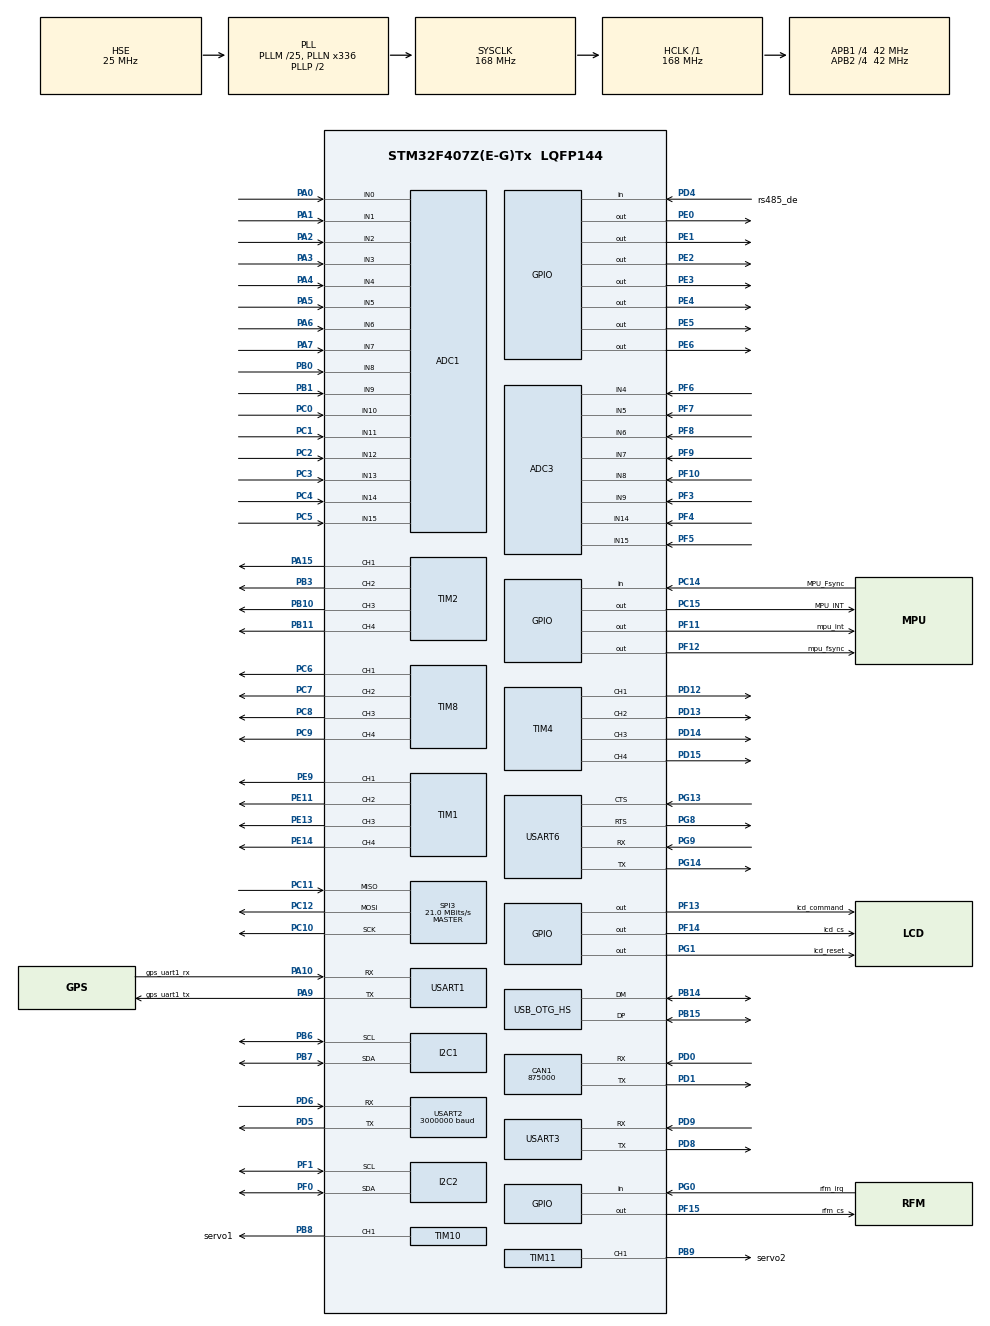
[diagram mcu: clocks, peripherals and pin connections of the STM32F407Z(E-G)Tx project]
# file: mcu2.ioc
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ADC1.ClockPrescaler=ADC_CLOCK_SYNC_PCLK_DIV4
ADC1.Rank-1\#ChannelRegularConversion=1
ADC1.master=1
ADC2.Channel-3\#ChannelRegularConversion=ADC_CHANNEL_0
ADC2.ClockPrescaler=ADC_CLOCK_SYNC_PCLK_DIV4
ADC2.NbrOfConversionFlag=1
ADC2.Rank-3\#ChannelRegularConversion=1
ADC2.SamplingTime-3\#ChannelRegularConversion=ADC_SAMPLETIME_3CYCLES
ADC3.Channel-0\#ChannelRegularConversion=ADC_CHANNEL_0
ADC3.ClockPrescaler=ADC_CLOCK_SYNC_PCLK_DIV4
ADC3.NbrOfConversionFlag=1
ADC3.Rank-0\#ChannelRegularConversion=1
ADC3.SamplingTime-0\#ChannelRegularConversion=ADC_SAMPLETIME_3CYCLES
CAN1.BS1=CAN_BS1_1TQ
CAN1.BS2=CAN_BS2_1TQ
CAN1.CalculateBaudRate=875000
CAN1.CalculateTimeBit=1142
CAN1.CalculateTimeQuantum=380.95238095238096
Dma.ADC1.2.Direction=DMA_PERIPH_TO_MEMORY
Dma.ADC1.2.FIFOMode=DMA_FIFOMODE_ENABLE
Dma.ADC1.2.FIFOThreshold=DMA_FIFO_THRESHOLD_FULL
Dma.ADC1.2.Instance=DMA2_Stream0
Dma.ADC1.2.MemBurst=DMA_MBURST_SINGLE
Dma.ADC1.2.MemDataAlignment=DMA_MDATAALIGN_HALFWORD
Dma.ADC1.2.MemInc=DMA_MINC_ENABLE
Dma.ADC1.2.Mode=DMA_CIRCULAR
Dma.ADC1.2.PeriphBurst=DMA_PBURST_SINGLE
Dma.ADC1.2.PeriphDataAlignment=DMA_PDATAALIGN_HALFWORD
Dma.ADC1.2.PeriphInc=DMA_PINC_DISABLE
Dma.ADC1.2.Priority=DMA_PRIORITY_LOW
Dma.ADC2.3.Direction=DMA_PERIPH_TO_MEMORY
Dma.ADC2.3.FIFOMode=DMA_FIFOMODE_ENABLE
Dma.ADC2.3.FIFOThreshold=DMA_FIFO_THRESHOLD_FULL
Dma.ADC2.3.Instance=DMA2_Stream2
Dma.ADC2.3.MemBurst=DMA_MBURST_SINGLE
Dma.ADC2.3.MemDataAlignment=DMA_MDATAALIGN_HALFWORD
Dma.ADC2.3.MemInc=DMA_MINC_ENABLE
Dma.ADC2.3.Mode=DMA_CIRCULAR
Dma.ADC2.3.PeriphBurst=DMA_PBURST_SINGLE
Dma.ADC2.3.PeriphDataAlignment=DMA_PDATAALIGN_HALFWORD
Dma.ADC2.3.PeriphInc=DMA_PINC_DISABLE
Dma.ADC2.3.Priority=DMA_PRIORITY_LOW
Dma.ADC3.4.Direction=DMA_PERIPH_TO_MEMORY
Dma.ADC3.4.FIFOMode=DMA_FIFOMODE_ENABLE
Dma.ADC3.4.FIFOThreshold=DMA_FIFO_THRESHOLD_FULL
Dma.ADC3.4.Instance=DMA2_Stream1
Dma.ADC3.4.MemBurst=DMA_MBURST_SINGLE
Dma.ADC3.4.MemDataAlignment=DMA_MDATAALIGN_HALFWORD
Dma.ADC3.4.MemInc=DMA_MINC_ENABLE
Dma.ADC3.4.Mode=DMA_CIRCULAR
Dma.ADC3.4.PeriphBurst=DMA_PBURST_INC4
Dma.ADC3.4.PeriphDataAlignment=DMA_PDATAALIGN_HALFWORD
Dma.ADC3.4.PeriphInc=DMA_PINC_DISABLE
Dma.ADC3.4.Priority=DMA_PRIORITY_LOW
Dma.Request0=USART2_TX
Dma.Request1=USART2_RX
Dma.Request2=ADC1
Dma.Request3=ADC2
Dma.Request4=ADC3
Dma.USART2_RX.1.Direction=DMA_PERIPH_TO_MEMORY
Dma.USART2_RX.1.FIFOMode=DMA_FIFOMODE_ENABLE
Dma.USART2_RX.1.FIFOThreshold=DMA_FIFO_THRESHOLD_FULL
Dma.USART2_RX.1.Instance=DMA1_Stream5
Dma.USART2_RX.1.MemBurst=DMA_MBURST_SINGLE
Dma.USART2_RX.1.MemDataAlignment=DMA_MDATAALIGN_BYTE
Dma.USART2_RX.1.MemInc=DMA_MINC_ENABLE
Dma.USART2_RX.1.Mode=DMA_NORMAL
Dma.USART2_RX.1.PeriphBurst=DMA_PBURST_SINGLE
Dma.USART2_RX.1.PeriphDataAlignment=DMA_PDATAALIGN_BYTE
Dma.USART2_RX.1.PeriphInc=DMA_PINC_DISABLE
Dma.USART2_RX.1.Priority=DMA_PRIORITY_LOW
Dma.USART2_TX.0.Direction=DMA_MEMORY_TO_PERIPH
Dma.USART2_TX.0.FIFOMode=DMA_FIFOMODE_ENABLE
Dma.USART2_TX.0.FIFOThreshold=DMA_FIFO_THRESHOLD_FULL
Dma.USART2_TX.0.Instance=DMA1_Stream6
Dma.USART2_TX.0.MemBurst=DMA_MBURST_SINGLE
Dma.USART2_TX.0.MemDataAlignment=DMA_MDATAALIGN_BYTE
Dma.USART2_TX.0.MemInc=DMA_MINC_ENABLE
Dma.USART2_TX.0.Mode=DMA_CIRCULAR
Dma.USART2_TX.0.PeriphBurst=DMA_PBURST_SINGLE
Dma.USART2_TX.0.PeriphDataAlignment=DMA_PDATAALIGN_BYTE
Dma.USART2_TX.0.PeriphInc=DMA_PINC_DISABLE
Dma.USART2_TX.0.Priority=DMA_PRIORITY_LOW
Mcu.Family=STM32F4
Mcu.Name=STM32F407Z(E-G)Tx
Mcu.Package=LQFP144
NVIC.CAN1_RX0_IRQn=true\:0\:0\:false\:false\:true\:true\:true
NVIC.CAN1_RX1_IRQn=true\:0\:0\:false\:false\:true\:true\:true
NVIC.CAN1_SCE_IRQn=true\:0\:0\:false\:false\:true\:true\:true
NVIC.CAN1_TX_IRQn=true\:0\:0\:false\:false\:true\:true\:true
NVIC.DMA1_Stream5_IRQn=true\:0\:0\:false\:false\:true\:false\:true
NVIC.DMA1_Stream6_IRQn=true\:0\:0\:false\:false\:true\:false\:true
NVIC.DMA2_Stream0_IRQn=true\:0\:0\:false\:false\:true\:false\:true
NVIC.DMA2_Stream1_IRQn=true\:0\:0\:false\:false\:true\:false\:true
NVIC.DMA2_Stream2_IRQn=true\:0\:0\:false\:false\:true\:false\:true
NVIC.OTG_HS_IRQn=true\:0\:0\:false\:false\:true\:false\:true
NVIC.PriorityGroup=NVIC_PRIORITYGROUP_4
NVIC.TIM8_TRG_COM_TIM14_IRQn=true\:15\:0\:false\:false\:true\:false\:true
NVIC.TimeBase=TIM8_TRG_COM_TIM14_IRQn
NVIC.TimeBaseIP=TIM14
NVIC.USART2_IRQn=true\:0\:0\:false\:false\:true\:true\:true
PA0-WKUP.Signal=ADCx_IN0
PA1.Signal=ADCx_IN1
PA10.GPIO_Label=gps_uart1_rx
PA10.Mode=Asynchronous
PA10.Signal=USART1_RX
PA13.Mode=Serial_Wire
PA13.Signal=SYS_JTMS-SWDIO
PA14.Mode=Serial_Wire
PA14.Signal=SYS_JTCK-SWCLK
PA15.Signal=S_TIM2_CH1_ETR
PA2.Signal=ADCx_IN2
PA3.Signal=ADCx_IN3
PA4.Signal=ADCx_IN4
PA5.Signal=ADCx_IN5
PA6.Signal=ADCx_IN6
PA7.Signal=ADCx_IN7
PA9.GPIO_Label=gps_uart1_tx
PA9.Mode=Asynchronous
PA9.Signal=USART1_TX
PB0.Signal=ADCx_IN8
PB1.Signal=ADCx_IN9
PB10.Signal=S_TIM2_CH3
PB11.Signal=S_TIM2_CH4
PB14.Mode=Device_Only_FS
PB14.Signal=USB_OTG_HS_DM
PB15.Mode=Device_Only_FS
PB15.Signal=USB_OTG_HS_DP
PB3.Signal=S_TIM2_CH2
PB6.Mode=I2C
PB6.Signal=I2C1_SCL
PB7.Mode=I2C
PB7.Signal=I2C1_SDA
PB8.GPIO_Label=servo1
PB8.Signal=S_TIM10_CH1
PB9.GPIO_Label=servo2
PB9.Signal=S_TIM11_CH1
PC0.Signal=ADCx_IN10
PC1.Signal=ADCx_IN11
PC10.Mode=Full_Duplex_Master
PC10.Signal=SPI3_SCK
PC11.Mode=Full_Duplex_Master
PC11.Signal=SPI3_MISO
PC12.Mode=Full_Duplex_Master
PC12.Signal=SPI3_MOSI
PC14-OSC32_IN.GPIO_Label=MPU_Fsync
PC14-OSC32_IN.Signal=GPIO_Input
PC15-OSC32_OUT.GPIO_Label=MPU_INT
PC15-OSC32_OUT.Signal=GPIO_Output
PC2.Signal=ADCx_IN12
PC3.Signal=ADCx_IN13
PC4.Signal=ADCx_IN14
PC5.Signal=ADCx_IN15
PC6.Signal=S_TIM8_CH1
PC7.Signal=S_TIM8_CH2
PC8.Signal=S_TIM8_CH3
PC9.Signal=S_TIM8_CH4
PD0.Mode=CAN_Activate
PD0.Signal=CAN1_RX
PD1.Mode=CAN_Activate
PD1.Signal=CAN1_TX
PD12.Signal=S_TIM4_CH1
PD13.Signal=S_TIM4_CH2
PD14.Signal=S_TIM4_CH3
PD15.Signal=S_TIM4_CH4
PD4.GPIO_Label=rs485_de
PD4.Signal=GPIO_Input
PD5.Mode=Asynchronous
PD5.Signal=USART2_TX
PD6.Mode=Asynchronous
PD6.Signal=USART2_RX
PD8.Mode=Asynchronous
PD8.Signal=USART3_TX
PD9.Mode=Asynchronous
PD9.Signal=USART3_RX
PE0.Signal=GPIO_Output
PE1.Signal=GPIO_Output
PE11.Signal=S_TIM1_CH2
PE13.Signal=S_TIM1_CH3
PE14.Signal=S_TIM1_CH4
PE2.Signal=GPIO_Output
PE3.Signal=GPIO_Output
PE4.Signal=GPIO_Output
PE5.Signal=GPIO_Output
PE6.Signal=GPIO_Output
PE9.Signal=S_TIM1_CH1
PF0.Mode=I2C
PF0.Signal=I2C2_SDA
PF1.Mode=I2C
PF1.Signal=I2C2_SCL
PF10.Mode=IN8
PF10.Signal=ADC3_IN8
PF11.GPIO_Label=mpu_int
PF11.Signal=GPIO_Output
PF12.GPIO_Label=mpu_fsync
PF12.Signal=GPIO_Output
PF13.GPIO_Label=lcd_command
PF13.Signal=GPIO_Output
PF14.GPIO_Label=lcd_cs
PF14.Signal=GPIO_Output
PF15.GPIO_Label=rfm_cs
PF15.Signal=GPIO_Output
PF3.Mode=IN9
PF3.Signal=ADC3_IN9
PF4.Mode=IN14
PF4.Signal=ADC3_IN14
PF5.Mode=IN15
PF5.Signal=ADC3_IN15
PF6.Mode=IN4
PF6.Signal=ADC3_IN4
PF7.Mode=IN5
PF7.Signal=ADC3_IN5
PF8.Mode=IN6
PF8.Signal=ADC3_IN6
PF9.Mode=IN7
PF9.Signal=ADC3_IN7
PG0.GPIO_Label=rfm_irq
PG0.Signal=GPIO_Input
PG1.GPIO_Label=lcd_reset
PG1.Signal=GPIO_Output
PG13.Mode=CTS_RTS
PG13.Signal=USART6_CTS
PG14.Mode=Asynchronous
PG14.Signal=USART6_TX
PG8.Mode=CTS_RTS
PG8.Signal=USART6_RTS
PG9.Mode=Asynchronous
PG9.Signal=USART6_RX
PH0-OSC_IN.Mode=HSE-External-Oscillator
PH0-OSC_IN.Signal=RCC_OSC_IN
PH1-OSC_OUT.Mode=HSE-External-Oscillator
PH1-OSC_OUT.Signal=RCC_OSC_OUT
ProjectManager.HeapSize=0x200
ProjectManager.StackSize=0x400
ProjectManager.TargetToolchain=SW4STM32
RCC.48MHZClocksFreq_Value=48000000
RCC.AHBFreq_Value=168000000
RCC.APB1CLKDivider=RCC_HCLK_DIV4
RCC.APB1Freq_Value=42000000
RCC.APB1TimFreq_Value=84000000
RCC.APB2CLKDivider=RCC_HCLK_DIV4
RCC.APB2Freq_Value=42000000
RCC.APB2TimFreq_Value=84000000
RCC.CortexFreq_Value=168000000
RCC.HCLKFreq_Value=168000000
RCC.HSE_VALUE=25000000
RCC.HSI_VALUE=16000000
RCC.LSE_VALUE=32768
RCC.PLLM=25
RCC.PLLN=336
RCC.PLLQ=7
RCC.SYSCLKFreq_VALUE=168000000
RCC.SYSCLKSource=RCC_SYSCLKSOURCE_PLLCLK
RCC.VCOOutputFreq_Value=336000000
SH.ADCx_IN0.0=ADC1_IN0,IN0
SH.ADCx_IN0.1=ADC3_IN0,IN0
SH.ADCx_IN0.2=ADC2_IN0,IN0
SH.ADCx_IN1.0=ADC1_IN1,IN1
SH.ADCx_IN1.1=ADC3_IN1,IN1
SH.ADCx_IN1.2=ADC2_IN1,IN1
SH.ADCx_IN10.0=ADC1_IN10,IN10
SH.ADCx_IN10.1=ADC3_IN10,IN10
SH.ADCx_IN10.2=ADC2_IN10,IN10
SH.ADCx_IN11.0=ADC1_IN11,IN11
SH.ADCx_IN11.1=ADC3_IN11,IN11
SH.ADCx_IN11.2=ADC2_IN11,IN11
SH.ADCx_IN12.0=ADC1_IN12,IN12
SH.ADCx_IN12.1=ADC3_IN12,IN12
SH.ADCx_IN12.2=ADC2_IN12,IN12
SH.ADCx_IN13.0=ADC1_IN13,IN13
SH.ADCx_IN13.1=ADC3_IN13,IN13
SH.ADCx_IN13.2=ADC2_IN13,IN13
SH.ADCx_IN14.0=ADC1_IN14,IN14
SH.ADCx_IN14.1=ADC2_IN14,IN14
SH.ADCx_IN15.0=ADC1_IN15,IN15
SH.ADCx_IN15.1=ADC2_IN15,IN15
SH.ADCx_IN2.0=ADC1_IN2,IN2
SH.ADCx_IN2.1=ADC3_IN2,IN2
SH.ADCx_IN2.2=ADC2_IN2,IN2
SH.ADCx_IN3.0=ADC1_IN3,IN3
SH.ADCx_IN3.1=ADC3_IN3,IN3
SH.ADCx_IN3.2=ADC2_IN3,IN3
SH.ADCx_IN4.0=ADC1_IN4,IN4
SH.ADCx_IN4.1=ADC2_IN4,IN4
SH.ADCx_IN5.0=ADC1_IN5,IN5
SH.ADCx_IN5.1=ADC2_IN5,IN5
SH.ADCx_IN6.0=ADC1_IN6,IN6
SH.ADCx_IN6.1=ADC2_IN6,IN6
SH.ADCx_IN7.0=ADC1_IN7,IN7
SH.ADCx_IN7.1=ADC2_IN7,IN7
SH.ADCx_IN8.0=ADC1_IN8,IN8
SH.ADCx_IN8.1=ADC2_IN8,IN8
SH.ADCx_IN9.0=ADC1_IN9,IN9
SH.ADCx_IN9.1=ADC2_IN9,IN9
SH.S_TIM10_CH1.0=TIM10_CH1,PWM Generation1 CH1
SH.S_TIM11_CH1.0=TIM11_CH1,PWM Generation1 CH1
SH.S_TIM1_CH1.0=TIM1_CH1,PWM Generation1 CH1
SH.S_TIM1_CH2.0=TIM1_CH2,PWM Generation2 CH2
SH.S_TIM1_CH3.0=TIM1_CH3,PWM Generation3 CH3
SH.S_TIM1_CH4.0=TIM1_CH4,PWM Generation4 CH4
SH.S_TIM2_CH1_ETR.0=TIM2_CH1,PWM Generation1 CH1
SH.S_TIM2_CH2.0=TIM2_CH2,PWM Generation2 CH2
SH.S_TIM2_CH3.0=TIM2_CH3,PWM Generation3 CH3
SH.S_TIM2_CH4.0=TIM2_CH4,PWM Generation4 CH4
SH.S_TIM4_CH1.0=TIM4_CH1,PWM Generation1 CH1
SH.S_TIM4_CH2.0=TIM4_CH2,PWM Generation2 CH2
SH.S_TIM4_CH3.0=TIM4_CH3,PWM Generation3 CH3
SH.S_TIM4_CH4.0=TIM4_CH4,PWM Generation4 CH4
SH.S_TIM8_CH1.0=TIM8_CH1,PWM Generation1 CH1
SH.S_TIM8_CH2.0=TIM8_CH2,PWM Generation2 CH2
SH.S_TIM8_CH3.0=TIM8_CH3,PWM Generation3 CH3
SH.S_TIM8_CH4.0=TIM8_CH4,PWM Generation4 CH4
SPI3.BaudRatePrescaler=SPI_BAUDRATEPRESCALER_2
SPI3.CalculateBaudRate=21.0 MBits/s
SPI3.Direction=SPI_DIRECTION_2LINES
SPI3.Mode=SPI_MODE_MASTER
SPI3.VirtualType=VM_MASTER
TIM1.AutoReloadPreload=TIM_AUTORELOAD_PRELOAD_ENABLE
TIM1.Channel-PWM\ Generation1\ CH1=TIM_CHANNEL_1
TIM1.Channel-PWM\ Generation2\ CH2=TIM_CHANNEL_2
TIM1.Channel-PWM\ Generation3\ CH3=TIM_CHANNEL_3
TIM1.Channel-PWM\ Generation4\ CH4=TIM_CHANNEL_4
TIM1.CounterMode=TIM_COUNTERMODE_CENTERALIGNED1
TIM10.Channel=TIM_CHANNEL_1
TIM11.Channel=TIM_CHANNEL_1
TIM2.Channel-PWM\ Generation1\ CH1=TIM_CHANNEL_1
TIM2.Channel-PWM\ Generation2\ CH2=TIM_CHANNEL_2
TIM2.Channel-PWM\ Generation3\ CH3=TIM_CHANNEL_3
TIM2.Channel-PWM\ Generation4\ CH4=TIM_CHANNEL_4
TIM4.Channel-PWM\ Generation1\ CH1=TIM_CHANNEL_1
TIM4.Channel-PWM\ Generation2\ CH2=TIM_CHANNEL_2
TIM4.Channel-PWM\ Generation3\ CH3=TIM_CHANNEL_3
TIM4.Channel-PWM\ Generation4\ CH4=TIM_CHANNEL_4
TIM8.Channel-PWM\ Generation1\ CH1=TIM_CHANNEL_1
TIM8.Channel-PWM\ Generation2\ CH2=TIM_CHANNEL_2
TIM8.Channel-PWM\ Generation3\ CH3=TIM_CHANNEL_3
TIM8.Channel-PWM\ Generation4\ CH4=TIM_CHANNEL_4
USART1.OverSampling=UART_OVERSAMPLING_16
USART1.VirtualMode=VM_ASYNC
USART2.BaudRate=3000000
USART2.OverSampling=UART_OVERSAMPLING_8
USART2.VirtualMode=VM_ASYNC
USART3.VirtualMode=VM_ASYNC
USART6.VirtualMode=VM_ASYNC
USB_DEVICE.CLASS_NAME_HS=CDC
USB_DEVICE.VirtualMode-CDC_HS=Cdc
USB_DEVICE.VirtualModeHS=Cdc_HS
USB_OTG_HS.VirtualMode-Device_Only_FS=Device_Only_FS
VP_ADC1_TempSens_Input.Mode=IN-TempSens
VP_ADC1_Vbat_Input.Mode=IN-Vbat
VP_ADC1_Vref_Input.Mode=IN-Vrefint
VP_IWDG_VS_IWDG.Mode=IWDG_Activate
VP_SYS_VS_tim14.Mode=TIM14
VP_TIM10_VS_ClockSourceINT.Mode=Enable_Timer
VP_TIM11_VS_ClockSourceINT.Mode=Enable_Timer
VP_TIM1_VS_ClockSourceINT.Mode=Internal
VP_TIM2_VS_ClockSourceITR.Mode=TriggerSource_ITR1
VP_TIM3_VS_ClockSourceINT.Mode=Internal
VP_TIM4_VS_ClockSourceINT.Mode=Internal
VP_TIM8_VS_ClockSourceINT.Mode=Internal
VP_USB_DEVICE_VS_USB_DEVICE_CDC_HS.Mode=CDC_HS
board=custom

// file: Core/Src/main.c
/* USER CODE BEGIN Header */
/**
  ******************************************************************************
  * @file           : main.c
  * @brief          : Main program body
  ******************************************************************************
  * @attention
  *
  * Copyright (c) 2022 STMicroelectronics.
  * All rights reserved.
  *
  * This software is licensed under terms that can be found in the LICENSE file
  * in the root directory of this software component.
  * If no LICENSE file comes with this software, it is provided AS-IS.
  *
  ******************************************************************************
  */
#include "cppmain.h"
/* USER CODE END Header */
#include "main.h"
#include "usb_device.h"

ADC_HandleTypeDef hadc1;
ADC_HandleTypeDef hadc2;
ADC_HandleTypeDef hadc3;
DMA_HandleTypeDef hdma_adc1;
DMA_HandleTypeDef hdma_adc2;
DMA_HandleTypeDef hdma_adc3;

CAN_HandleTypeDef hcan1;

I2C_HandleTypeDef hi2c1;
I2C_HandleTypeDef hi2c2;

IWDG_HandleTypeDef hiwdg;

SPI_HandleTypeDef hspi3;

TIM_HandleTypeDef htim1;
TIM_HandleTypeDef htim2;
TIM_HandleTypeDef htim3;
TIM_HandleTypeDef htim4;
TIM_HandleTypeDef htim8;
TIM_HandleTypeDef htim10;
TIM_HandleTypeDef htim11;

UART_HandleTypeDef huart1;
UART_HandleTypeDef huart2;
UART_HandleTypeDef huart3;
UART_HandleTypeDef huart6;
DMA_HandleTypeDef hdma_usart2_tx;
DMA_HandleTypeDef hdma_usart2_rx;

void SystemClock_Config(void);
static void MX_GPIO_Init(void);
static void MX_ADC1_Init(void);
static void MX_CAN1_Init(void);
static void MX_TIM1_Init(void);
static void MX_TIM2_Init(void);
static void MX_TIM3_Init(void);
static void MX_TIM4_Init(void);
static void MX_ADC3_Init(void);
static void MX_I2C2_Init(void);
static void MX_IWDG_Init(void);
static void MX_TIM8_Init(void);
static void MX_USART1_UART_Init(void);
static void MX_USART2_UART_Init(void);
static void MX_USART3_UART_Init(void);
static void MX_USART6_UART_Init(void);
static void MX_ADC2_Init(void);
static void MX_I2C1_Init(void);
static void MX_SPI3_Init(void);
static void MX_TIM10_Init(void);
static void MX_TIM11_Init(void);
static void MX_DMA_Init(void);

int main(void)
{

    /* MCU Configuration--------------------------------------------------------*/

    /* Reset of all peripherals, Initializes the Flash interface and the Systick. */
    HAL_Init();

    /* Configure the system clock */
    SystemClock_Config();

    /* Initialize all configured peripherals */
    MX_GPIO_Init();
    MX_ADC1_Init();
    MX_CAN1_Init();
    MX_TIM1_Init();
    MX_TIM2_Init();
    MX_TIM3_Init();
    MX_TIM4_Init();
    MX_ADC3_Init();
    MX_I2C2_Init();
    MX_IWDG_Init();
    MX_TIM8_Init();
    MX_USART1_UART_Init();
    MX_USART2_UART_Init();
    MX_USART3_UART_Init();
    MX_USART6_UART_Init();
    MX_ADC2_Init();
    MX_I2C1_Init();
    MX_SPI3_Init();
    MX_TIM10_Init();
    MX_TIM11_Init();
    MX_DMA_Init();
    MX_USB_DEVICE_Init();
    /* USER CODE BEGIN 2 */
    // send pointers to hardware to the main task
    uint32_t tickCounter = 0;
    struct p_HW hardware = {.adc1         = &hadc1,
                            .adc2         = &hadc2,
                            .adc3         = &hadc3,
                            .can1         = &hcan1,
                            .i2c1         = &hi2c1,
                            .i2c2         = &hi2c2,
                            .iwdg         = &hiwdg,
                            .spi3         = &hspi3,
                            .tim1         = &htim1,
                            .tim2         = &htim2,
                            .tim3         = &htim3,
                            .tim4         = &htim4,
                            .tim8         = &htim8,
                            .tim10        = &htim10,
                            .tim11        = &htim11,
                            .uart1        = &huart1,
                            .uart2        = &huart2,
                            .uart3        = &huart3,
                            .uart6        = &huart6,
                            .pTickCounter = &tickCounter};
#ifdef USE_LED_TICK
    void HAL_SYSTICK_Callback(void)
    {
        // invert gpio3 pin4
        //HAL_GPIO_TogglePin(GPIOE, GPIO_PIN_4);
        my_systick_Callback();
        tickCounter++;
        //        HAL_IncTick();
        //        HAL_SYSTICK_IRQHandler();
        //ledPatern();
    }
#endif
    /* USER CODE END 2 */

    cppmain(hardware);
    /* Infinite loop */
    /* USER CODE BEGIN WHILE */
    uint8_t ledCounter = 10u;
    while (1)
    {
        //        const uint8_t lastCount = ledCounter;
        ledCounter++;

        // kick watchdog
        HAL_IWDG_Refresh(&hiwdg);
        /* USER CODE END WHILE */

    }
}

void SystemClock_Config(void)
{
    RCC_OscInitTypeDef RCC_OscInitStruct = {0};
    RCC_ClkInitTypeDef RCC_ClkInitStruct = {0};

    /** Configure the main internal regulator output voltage
  */
    __HAL_RCC_PWR_CLK_ENABLE();
    __HAL_PWR_VOLTAGESCALING_CONFIG(PWR_REGULATOR_VOLTAGE_SCALE1);
    /** Initializes the RCC Oscillators according to the specified parameters
  * in the RCC_OscInitTypeDef structure.
  */
    RCC_OscInitStruct.OscillatorType = RCC_OSCILLATORTYPE_LSI | RCC_OSCILLATORTYPE_HSE;
    RCC_OscInitStruct.HSEState       = RCC_HSE_ON;
    RCC_OscInitStruct.LSIState       = RCC_LSI_ON;
    RCC_OscInitStruct.PLL.PLLState   = RCC_PLL_ON;
    RCC_OscInitStruct.PLL.PLLSource  = RCC_PLLSOURCE_HSE;
    RCC_OscInitStruct.PLL.PLLM       = 25;
    RCC_OscInitStruct.PLL.PLLN       = 336;
    RCC_OscInitStruct.PLL.PLLP       = RCC_PLLP_DIV2;
    RCC_OscInitStruct.PLL.PLLQ       = 7;
    if (HAL_RCC_OscConfig(&RCC_OscInitStruct) != HAL_OK)
    {
        Error_Handler();
    }
    /** Initializes the CPU, AHB and APB buses clocks
  */
    RCC_ClkInitStruct.ClockType      = RCC_CLOCKTYPE_HCLK | RCC_CLOCKTYPE_SYSCLK | RCC_CLOCKTYPE_PCLK1 | RCC_CLOCKTYPE_PCLK2;
    RCC_ClkInitStruct.SYSCLKSource   = RCC_SYSCLKSOURCE_PLLCLK;
    RCC_ClkInitStruct.AHBCLKDivider  = RCC_SYSCLK_DIV1;
    RCC_ClkInitStruct.APB1CLKDivider = RCC_HCLK_DIV4;
    RCC_ClkInitStruct.APB2CLKDivider = RCC_HCLK_DIV4;

    if (HAL_RCC_ClockConfig(&RCC_ClkInitStruct, FLASH_LATENCY_5) != HAL_OK)
    {
        Error_Handler();
    }
}

static void MX_ADC1_Init(void)
{

    ADC_ChannelConfTypeDef sConfig = {0};

    /** Configure the global features of the ADC (Clock, Resolution, Data Alignment and number of conversion)
  */
    hadc1.Instance                   = ADC1;
    hadc1.Init.ClockPrescaler        = ADC_CLOCK_SYNC_PCLK_DIV4;
    hadc1.Init.Resolution            = ADC_RESOLUTION_12B;
    hadc1.Init.ScanConvMode          = DISABLE;
    hadc1.Init.ContinuousConvMode    = DISABLE;
    hadc1.Init.DiscontinuousConvMode = DISABLE;
    hadc1.Init.ExternalTrigConvEdge  = ADC_EXTERNALTRIGCONVEDGE_NONE;
    hadc1.Init.ExternalTrigConv      = ADC_SOFTWARE_START;
    hadc1.Init.DataAlign             = ADC_DATAALIGN_RIGHT;
    hadc1.Init.NbrOfConversion       = 1;
    hadc1.Init.DMAContinuousRequests = DISABLE;
    hadc1.Init.EOCSelection          = ADC_EOC_SINGLE_CONV;
    if (HAL_ADC_Init(&hadc1) != HAL_OK)
    {
        Error_Handler();
    }
    /** Configure for the selected ADC regular channel its corresponding rank in the sequencer and its sample time.
  */
    sConfig.Channel      = ADC_CHANNEL_0;
    sConfig.Rank         = 1;
    sConfig.SamplingTime = ADC_SAMPLETIME_3CYCLES;
    if (HAL_ADC_ConfigChannel(&hadc1, &sConfig) != HAL_OK)
    {
        Error_Handler();
    }
}

static void MX_ADC2_Init(void)
{

    ADC_ChannelConfTypeDef sConfig = {0};

    /** Configure the global features of the ADC (Clock, Resolution, Data Alignment and number of conversion)
  */
    hadc2.Instance                   = ADC2;
    hadc2.Init.ClockPrescaler        = ADC_CLOCK_SYNC_PCLK_DIV4;
    hadc2.Init.Resolution            = ADC_RESOLUTION_12B;
    hadc2.Init.ScanConvMode          = DISABLE;
    hadc2.Init.ContinuousConvMode    = DISABLE;
    hadc2.Init.DiscontinuousConvMode = DISABLE;
    hadc2.Init.ExternalTrigConvEdge  = ADC_EXTERNALTRIGCONVEDGE_NONE;
    hadc2.Init.ExternalTrigConv      = ADC_SOFTWARE_START;
    hadc2.Init.DataAlign             = ADC_DATAALIGN_RIGHT;
    hadc2.Init.NbrOfConversion       = 1;
    hadc2.Init.DMAContinuousRequests = DISABLE;
    hadc2.Init.EOCSelection          = ADC_EOC_SINGLE_CONV;
    if (HAL_ADC_Init(&hadc2) != HAL_OK)
    {
        Error_Handler();
    }
    /** Configure for the selected ADC regular channel its corresponding rank in the sequencer and its sample time.
  */
    sConfig.Channel      = ADC_CHANNEL_0;
    sConfig.Rank         = 1;
    sConfig.SamplingTime = ADC_SAMPLETIME_3CYCLES;
    if (HAL_ADC_ConfigChannel(&hadc2, &sConfig) != HAL_OK)
    {
        Error_Handler();
    }
}

static void MX_ADC3_Init(void)
{

    ADC_ChannelConfTypeDef sConfig = {0};

    /** Configure the global features of the ADC (Clock, Resolution, Data Alignment and number of conversion)
  */
    hadc3.Instance                   = ADC3;
    hadc3.Init.ClockPrescaler        = ADC_CLOCK_SYNC_PCLK_DIV4;
    hadc3.Init.Resolution            = ADC_RESOLUTION_12B;
    hadc3.Init.ScanConvMode          = DISABLE;
    hadc3.Init.ContinuousConvMode    = DISABLE;
    hadc3.Init.DiscontinuousConvMode = DISABLE;
    hadc3.Init.ExternalTrigConvEdge  = ADC_EXTERNALTRIGCONVEDGE_NONE;
    hadc3.Init.ExternalTrigConv      = ADC_SOFTWARE_START;
    hadc3.Init.DataAlign             = ADC_DATAALIGN_RIGHT;
    hadc3.Init.NbrOfConversion       = 1;
    hadc3.Init.DMAContinuousRequests = DISABLE;
    hadc3.Init.EOCSelection          = ADC_EOC_SINGLE_CONV;
    if (HAL_ADC_Init(&hadc3) != HAL_OK)
    {
        Error_Handler();
    }
    /** Configure for the selected ADC regular channel its corresponding rank in the sequencer and its sample time.
  */
    sConfig.Channel      = ADC_CHANNEL_0;
    sConfig.Rank         = 1;
    sConfig.SamplingTime = ADC_SAMPLETIME_3CYCLES;
    if (HAL_ADC_ConfigChannel(&hadc3, &sConfig) != HAL_OK)
    {
        Error_Handler();
    }
}

static void MX_CAN1_Init(void)
{

    hcan1.Instance                  = CAN1;
    hcan1.Init.Prescaler            = 16;
    hcan1.Init.Mode                 = CAN_MODE_NORMAL;
    hcan1.Init.SyncJumpWidth        = CAN_SJW_1TQ;
    hcan1.Init.TimeSeg1             = CAN_BS1_1TQ;
    hcan1.Init.TimeSeg2             = CAN_BS2_1TQ;
    hcan1.Init.TimeTriggeredMode    = DISABLE;
    hcan1.Init.AutoBusOff           = DISABLE;
    hcan1.Init.AutoWakeUp           = DISABLE;
    hcan1.Init.AutoRetransmission   = DISABLE;
    hcan1.Init.ReceiveFifoLocked    = DISABLE;
    hcan1.Init.TransmitFifoPriority = DISABLE;
    if (HAL_CAN_Init(&hcan1) != HAL_OK)
    {
        Error_Handler();
    }
}

static void MX_I2C1_Init(void)
{

    hi2c1.Instance             = I2C1;
    hi2c1.Init.ClockSpeed      = 100000;
    hi2c1.Init.DutyCycle       = I2C_DUTYCYCLE_2;
    hi2c1.Init.OwnAddress1     = 0;
    hi2c1.Init.AddressingMode  = I2C_ADDRESSINGMODE_7BIT;
    hi2c1.Init.DualAddressMode = I2C_DUALADDRESS_DISABLE;
    hi2c1.Init.OwnAddress2     = 0;
    hi2c1.Init.GeneralCallMode = I2C_GENERALCALL_DISABLE;
    hi2c1.Init.NoStretchMode   = I2C_NOSTRETCH_DISABLE;
    if (HAL_I2C_Init(&hi2c1) != HAL_OK)
    {
        Error_Handler();
    }
}

static void MX_I2C2_Init(void)
{

    hi2c2.Instance             = I2C2;
    hi2c2.Init.ClockSpeed      = 100000;
    hi2c2.Init.DutyCycle       = I2C_DUTYCYCLE_2;
    hi2c2.Init.OwnAddress1     = 0;
    hi2c2.Init.AddressingMode  = I2C_ADDRESSINGMODE_7BIT;
    hi2c2.Init.DualAddressMode = I2C_DUALADDRESS_DISABLE;
    hi2c2.Init.OwnAddress2     = 0;
    hi2c2.Init.GeneralCallMode = I2C_GENERALCALL_DISABLE;
    hi2c2.Init.NoStretchMode   = I2C_NOSTRETCH_DISABLE;
    if (HAL_I2C_Init(&hi2c2) != HAL_OK)
    {
        Error_Handler();
    }
}

static void MX_IWDG_Init(void)
{

    hiwdg.Instance       = IWDG;
    hiwdg.Init.Prescaler = IWDG_PRESCALER_4;
    hiwdg.Init.Reload    = 4095;
    if (HAL_IWDG_Init(&hiwdg) != HAL_OK)
    {
        Error_Handler();
    }
}

static void MX_SPI3_Init(void)
{

    /* SPI3 parameter configuration*/
    hspi3.Instance               = SPI3;
    hspi3.Init.Mode              = SPI_MODE_MASTER;
    hspi3.Init.Direction         = SPI_DIRECTION_2LINES;
    hspi3.Init.DataSize          = SPI_DATASIZE_8BIT;
    hspi3.Init.CLKPolarity       = SPI_POLARITY_LOW;
    hspi3.Init.CLKPhase          = SPI_PHASE_1EDGE;
    hspi3.Init.NSS               = SPI_NSS_SOFT;
    hspi3.Init.BaudRatePrescaler = SPI_BAUDRATEPRESCALER_2;
    hspi3.Init.FirstBit          = SPI_FIRSTBIT_MSB;
    hspi3.Init.TIMode            = SPI_TIMODE_DISABLE;
    hspi3.Init.CRCCalculation    = SPI_CRCCALCULATION_DISABLE;
    hspi3.Init.CRCPolynomial     = 10;
    if (HAL_SPI_Init(&hspi3) != HAL_OK)
    {
        Error_Handler();
    }
}

static void MX_TIM1_Init(void)
{

    TIM_ClockConfigTypeDef sClockSourceConfig           = {0};
    TIM_MasterConfigTypeDef sMasterConfig               = {0};
    TIM_OC_InitTypeDef sConfigOC                        = {0};
    TIM_BreakDeadTimeConfigTypeDef sBreakDeadTimeConfig = {0};

    htim1.Instance               = TIM1;
    htim1.Init.Prescaler         = 0;
    htim1.Init.CounterMode       = TIM_COUNTERMODE_CENTERALIGNED1;
    htim1.Init.Period            = 65535;
    htim1.Init.ClockDivision     = TIM_CLOCKDIVISION_DIV1;
    htim1.Init.RepetitionCounter = 0;
    htim1.Init.AutoReloadPreload = TIM_AUTORELOAD_PRELOAD_ENABLE;
    if (HAL_TIM_Base_Init(&htim1) != HAL_OK)
    {
        Error_Handler();
    }
    sClockSourceConfig.ClockSource = TIM_CLOCKSOURCE_INTERNAL;
    if (HAL_TIM_ConfigClockSource(&htim1, &sClockSourceConfig) != HAL_OK)
    {
        Error_Handler();
    }
    if (HAL_TIM_PWM_Init(&htim1) != HAL_OK)
    {
        Error_Handler();
    }
    sMasterConfig.MasterOutputTrigger = TIM_TRGO_RESET;
    sMasterConfig.MasterSlaveMode     = TIM_MASTERSLAVEMODE_DISABLE;
    if (HAL_TIMEx_MasterConfigSynchronization(&htim1, &sMasterConfig) != HAL_OK)
    {
        Error_Handler();
    }
    sConfigOC.OCMode       = TIM_OCMODE_PWM1;
    sConfigOC.Pulse        = 0;
    sConfigOC.OCPolarity   = TIM_OCPOLARITY_HIGH;
    sConfigOC.OCNPolarity  = TIM_OCNPOLARITY_HIGH;
    sConfigOC.OCFastMode   = TIM_OCFAST_DISABLE;
    sConfigOC.OCIdleState  = TIM_OCIDLESTATE_RESET;
    sConfigOC.OCNIdleState = TIM_OCNIDLESTATE_RESET;
    if (HAL_TIM_PWM_ConfigChannel(&htim1, &sConfigOC, TIM_CHANNEL_1) != HAL_OK)
    {
        Error_Handler();
    }
    if (HAL_TIM_PWM_ConfigChannel(&htim1, &sConfigOC, TIM_CHANNEL_2) != HAL_OK)
    {
        Error_Handler();
    }
    if (HAL_TIM_PWM_ConfigChannel(&htim1, &sConfigOC, TIM_CHANNEL_3) != HAL_OK)
    {
        Error_Handler();
    }
    if (HAL_TIM_PWM_ConfigChannel(&htim1, &sConfigOC, TIM_CHANNEL_4) != HAL_OK)
    {
        Error_Handler();
    }
    sBreakDeadTimeConfig.OffStateRunMode  = TIM_OSSR_DISABLE;
    sBreakDeadTimeConfig.OffStateIDLEMode = TIM_OSSI_DISABLE;
    sBreakDeadTimeConfig.LockLevel        = TIM_LOCKLEVEL_OFF;
    sBreakDeadTimeConfig.DeadTime         = 0;
    sBreakDeadTimeConfig.BreakState       = TIM_BREAK_DISABLE;
    sBreakDeadTimeConfig.BreakPolarity    = TIM_BREAKPOLARITY_HIGH;
    sBreakDeadTimeConfig.AutomaticOutput  = TIM_AUTOMATICOUTPUT_DISABLE;
    if (HAL_TIMEx_ConfigBreakDeadTime(&htim1, &sBreakDeadTimeConfig) != HAL_OK)
    {
        Error_Handler();
    }
    HAL_TIM_MspPostInit(&htim1);
}

static void MX_TIM2_Init(void)
{

    TIM_SlaveConfigTypeDef sSlaveConfig   = {0};
    TIM_MasterConfigTypeDef sMasterConfig = {0};
    TIM_OC_InitTypeDef sConfigOC          = {0};

    htim2.Instance               = TIM2;
    htim2.Init.Prescaler         = 0;
    htim2.Init.CounterMode       = TIM_COUNTERMODE_UP;
    htim2.Init.Period            = 4294967295;
    htim2.Init.ClockDivision     = TIM_CLOCKDIVISION_DIV1;
    htim2.Init.AutoReloadPreload = TIM_AUTORELOAD_PRELOAD_DISABLE;
    if (HAL_TIM_Base_Init(&htim2) != HAL_OK)
    {
        Error_Handler();
    }
    if (HAL_TIM_PWM_Init(&htim2) != HAL_OK)
    {
        Error_Handler();
    }
    sSlaveConfig.SlaveMode    = TIM_SLAVEMODE_DISABLE;
    sSlaveConfig.InputTrigger = TIM_TS_ITR1;
    if (HAL_TIM_SlaveConfigSynchro(&htim2, &sSlaveConfig) != HAL_OK)
    {
        Error_Handler();
    }
    sMasterConfig.MasterOutputTrigger = TIM_TRGO_RESET;
    sMasterConfig.MasterSlaveMode     = TIM_MASTERSLAVEMODE_DISABLE;
    if (HAL_TIMEx_MasterConfigSynchronization(&htim2, &sMasterConfig) != HAL_OK)
    {
        Error_Handler();
    }
    sConfigOC.OCMode     = TIM_OCMODE_PWM1;
    sConfigOC.Pulse      = 0;
    sConfigOC.OCPolarity = TIM_OCPOLARITY_HIGH;
    sConfigOC.OCFastMode = TIM_OCFAST_DISABLE;
    if (HAL_TIM_PWM_ConfigChannel(&htim2, &sConfigOC, TIM_CHANNEL_1) != HAL_OK)
    {
        Error_Handler();
    }
    if (HAL_TIM_PWM_ConfigChannel(&htim2, &sConfigOC, TIM_CHANNEL_2) != HAL_OK)
    {
        Error_Handler();
    }
    if (HAL_TIM_PWM_ConfigChannel(&htim2, &sConfigOC, TIM_CHANNEL_3) != HAL_OK)
    {
        Error_Handler();
    }
    if (HAL_TIM_PWM_ConfigChannel(&htim2, &sConfigOC, TIM_CHANNEL_4) != HAL_OK)
    {
        Error_Handler();
    }
    HAL_TIM_MspPostInit(&htim2);
}

static void MX_TIM3_Init(void)
{

    TIM_ClockConfigTypeDef sClockSourceConfig = {0};
    TIM_MasterConfigTypeDef sMasterConfig     = {0};

    htim3.Instance               = TIM3;
    htim3.Init.Prescaler         = 0;
    htim3.Init.CounterMode       = TIM_COUNTERMODE_UP;
    htim3.Init.Period            = 65535;
    htim3.Init.ClockDivision     = TIM_CLOCKDIVISION_DIV1;
    htim3.Init.AutoReloadPreload = TIM_AUTORELOAD_PRELOAD_DISABLE;
    if (HAL_TIM_Base_Init(&htim3) != HAL_OK)
    {
        Error_Handler();
    }
    sClockSourceConfig.ClockSource = TIM_CLOCKSOURCE_INTERNAL;
    if (HAL_TIM_ConfigClockSource(&htim3, &sClockSourceConfig) != HAL_OK)
    {
        Error_Handler();
    }
    sMasterConfig.MasterOutputTrigger = TIM_TRGO_RESET;
    sMasterConfig.MasterSlaveMode     = TIM_MASTERSLAVEMODE_DISABLE;
    if (HAL_TIMEx_MasterConfigSynchronization(&htim3, &sMasterConfig) != HAL_OK)
    {
        Error_Handler();
    }
}

static void MX_TIM4_Init(void)
{

    TIM_ClockConfigTypeDef sClockSourceConfig = {0};
    TIM_MasterConfigTypeDef sMasterConfig     = {0};
    TIM_OC_InitTypeDef sConfigOC              = {0};

    htim4.Instance               = TIM4;
    htim4.Init.Prescaler         = 0;
    htim4.Init.CounterMode       = TIM_COUNTERMODE_UP;
    htim4.Init.Period            = 65535;
    htim4.Init.ClockDivision     = TIM_CLOCKDIVISION_DIV1;
    htim4.Init.AutoReloadPreload = TIM_AUTORELOAD_PRELOAD_DISABLE;
    if (HAL_TIM_Base_Init(&htim4) != HAL_OK)
    {
        Error_Handler();
    }
    sClockSourceConfig.ClockSource = TIM_CLOCKSOURCE_INTERNAL;
    if (HAL_TIM_ConfigClockSource(&htim4, &sClockSourceConfig) != HAL_OK)
    {
        Error_Handler();
    }
    if (HAL_TIM_PWM_Init(&htim4) != HAL_OK)
    {
        Error_Handler();
    }
    sMasterConfig.MasterOutputTrigger = TIM_TRGO_RESET;
    sMasterConfig.MasterSlaveMode     = TIM_MASTERSLAVEMODE_DISABLE;
    if (HAL_TIMEx_MasterConfigSynchronization(&htim4, &sMasterConfig) != HAL_OK)
    {
        Error_Handler();
    }
    sConfigOC.OCMode     = TIM_OCMODE_PWM1;
    sConfigOC.Pulse      = 0;
    sConfigOC.OCPolarity = TIM_OCPOLARITY_HIGH;
    sConfigOC.OCFastMode = TIM_OCFAST_DISABLE;
    if (HAL_TIM_PWM_ConfigChannel(&htim4, &sConfigOC, TIM_CHANNEL_1) != HAL_OK)
    {
        Error_Handler();
    }
    if (HAL_TIM_PWM_ConfigChannel(&htim4, &sConfigOC, TIM_CHANNEL_2) != HAL_OK)
    {
        Error_Handler();
    }
    if (HAL_TIM_PWM_ConfigChannel(&htim4, &sConfigOC, TIM_CHANNEL_3) != HAL_OK)
    {
        Error_Handler();
    }
    if (HAL_TIM_PWM_ConfigChannel(&htim4, &sConfigOC, TIM_CHANNEL_4) != HAL_OK)
    {
        Error_Handler();
    }
    HAL_TIM_MspPostInit(&htim4);
}

static void MX_TIM8_Init(void)
{

    TIM_ClockConfigTypeDef sClockSourceConfig           = {0};
    TIM_MasterConfigTypeDef sMasterConfig               = {0};
    TIM_OC_InitTypeDef sConfigOC                        = {0};
    TIM_BreakDeadTimeConfigTypeDef sBreakDeadTimeConfig = {0};

    htim8.Instance               = TIM8;
    htim8.Init.Prescaler         = 0;
    htim8.Init.CounterMode       = TIM_COUNTERMODE_UP;
    htim8.Init.Period            = 65535;
    htim8.Init.ClockDivision     = TIM_CLOCKDIVISION_DIV1;
    htim8.Init.RepetitionCounter = 0;
    htim8.Init.AutoReloadPreload = TIM_AUTORELOAD_PRELOAD_DISABLE;
    if (HAL_TIM_Base_Init(&htim8) != HAL_OK)
    {
        Error_Handler();
    }
    sClockSourceConfig.ClockSource = TIM_CLOCKSOURCE_INTERNAL;
    if (HAL_TIM_ConfigClockSource(&htim8, &sClockSourceConfig) != HAL_OK)
    {
        Error_Handler();
    }
    if (HAL_TIM_PWM_Init(&htim8) != HAL_OK)
    {
        Error_Handler();
    }
    sMasterConfig.MasterOutputTrigger = TIM_TRGO_RESET;
    sMasterConfig.MasterSlaveMode     = TIM_MASTERSLAVEMODE_DISABLE;
    if (HAL_TIMEx_MasterConfigSynchronization(&htim8, &sMasterConfig) != HAL_OK)
    {
        Error_Handler();
    }
    sConfigOC.OCMode       = TIM_OCMODE_PWM1;
    sConfigOC.Pulse        = 0;
    sConfigOC.OCPolarity   = TIM_OCPOLARITY_HIGH;
    sConfigOC.OCNPolarity  = TIM_OCNPOLARITY_HIGH;
    sConfigOC.OCFastMode   = TIM_OCFAST_DISABLE;
    sConfigOC.OCIdleState  = TIM_OCIDLESTATE_RESET;
    sConfigOC.OCNIdleState = TIM_OCNIDLESTATE_RESET;
    if (HAL_TIM_PWM_ConfigChannel(&htim8, &sConfigOC, TIM_CHANNEL_1) != HAL_OK)
    {
        Error_Handler();
    }
    if (HAL_TIM_PWM_ConfigChannel(&htim8, &sConfigOC, TIM_CHANNEL_2) != HAL_OK)
    {
        Error_Handler();
    }
    if (HAL_TIM_PWM_ConfigChannel(&htim8, &sConfigOC, TIM_CHANNEL_3) != HAL_OK)
    {
        Error_Handler();
    }
    if (HAL_TIM_PWM_ConfigChannel(&htim8, &sConfigOC, TIM_CHANNEL_4) != HAL_OK)
    {
        Error_Handler();
    }
    sBreakDeadTimeConfig.OffStateRunMode  = TIM_OSSR_DISABLE;
    sBreakDeadTimeConfig.OffStateIDLEMode = TIM_OSSI_DISABLE;
    sBreakDeadTimeConfig.LockLevel        = TIM_LOCKLEVEL_OFF;
    sBreakDeadTimeConfig.DeadTime         = 0;
    sBreakDeadTimeConfig.BreakState       = TIM_BREAK_DISABLE;
    sBreakDeadTimeConfig.BreakPolarity    = TIM_BREAKPOLARITY_HIGH;
    sBreakDeadTimeConfig.AutomaticOutput  = TIM_AUTOMATICOUTPUT_DISABLE;
    if (HAL_TIMEx_ConfigBreakDeadTime(&htim8, &sBreakDeadTimeConfig) != HAL_OK)
    {
        Error_Handler();
    }
    HAL_TIM_MspPostInit(&htim8);
}

static void MX_TIM10_Init(void)
{

    TIM_OC_InitTypeDef sConfigOC = {0};

    htim10.Instance               = TIM10;
    htim10.Init.Prescaler         = 0;
    htim10.Init.CounterMode       = TIM_COUNTERMODE_UP;
    htim10.Init.Period            = 65535;
    htim10.Init.ClockDivision     = TIM_CLOCKDIVISION_DIV1;
    htim10.Init.AutoReloadPreload = TIM_AUTORELOAD_PRELOAD_DISABLE;
    if (HAL_TIM_Base_Init(&htim10) != HAL_OK)
    {
        Error_Handler();
    }
    if (HAL_TIM_PWM_Init(&htim10) != HAL_OK)
    {
        Error_Handler();
    }
    sConfigOC.OCMode     = TIM_OCMODE_PWM1;
    sConfigOC.Pulse      = 0;
    sConfigOC.OCPolarity = TIM_OCPOLARITY_HIGH;
    sConfigOC.OCFastMode = TIM_OCFAST_DISABLE;
    if (HAL_TIM_PWM_ConfigChannel(&htim10, &sConfigOC, TIM_CHANNEL_1) != HAL_OK)
    {
        Error_Handler();
    }
    HAL_TIM_MspPostInit(&htim10);
}

static void MX_TIM11_Init(void)
{

    TIM_OC_InitTypeDef sConfigOC = {0};

    htim11.Instance               = TIM11;
    htim11.Init.Prescaler         = 0;
    htim11.Init.CounterMode       = TIM_COUNTERMODE_UP;
    htim11.Init.Period            = 65535;
    htim11.Init.ClockDivision     = TIM_CLOCKDIVISION_DIV1;
    htim11.Init.AutoReloadPreload = TIM_AUTORELOAD_PRELOAD_DISABLE;
    if (HAL_TIM_Base_Init(&htim11) != HAL_OK)
    {
        Error_Handler();
    }
    if (HAL_TIM_PWM_Init(&htim11) != HAL_OK)
    {
        Error_Handler();
    }
    sConfigOC.OCMode     = TIM_OCMODE_PWM1;
    sConfigOC.Pulse      = 0;
    sConfigOC.OCPolarity = TIM_OCPOLARITY_HIGH;
    sConfigOC.OCFastMode = TIM_OCFAST_DISABLE;
    if (HAL_TIM_PWM_ConfigChannel(&htim11, &sConfigOC, TIM_CHANNEL_1) != HAL_OK)
    {
        Error_Handler();
    }
    HAL_TIM_MspPostInit(&htim11);
}

static void MX_USART1_UART_Init(void)
{

    huart1.Instance          = USART1;
    huart1.Init.BaudRate     = 115200;
    huart1.Init.WordLength   = UART_WORDLENGTH_8B;
    huart1.Init.StopBits     = UART_STOPBITS_1;
    huart1.Init.Parity       = UART_PARITY_NONE;
    huart1.Init.Mode         = UART_MODE_TX_RX;
    huart1.Init.HwFlowCtl    = UART_HWCONTROL_NONE;
    huart1.Init.OverSampling = UART_OVERSAMPLING_16;
    if (HAL_UART_Init(&huart1) != HAL_OK)
    {
        Error_Handler();
    }
}

static void MX_USART2_UART_Init(void)
{

    huart2.Instance          = USART2;
    huart2.Init.BaudRate     = 3000000;
    huart2.Init.WordLength   = UART_WORDLENGTH_8B;
    huart2.Init.StopBits     = UART_STOPBITS_1;
    huart2.Init.Parity       = UART_PARITY_NONE;
    huart2.Init.Mode         = UART_MODE_TX_RX;
    huart2.Init.HwFlowCtl    = UART_HWCONTROL_NONE;
    huart2.Init.OverSampling = UART_OVERSAMPLING_8;
    if (HAL_UART_Init(&huart2) != HAL_OK)
    {
        Error_Handler();
    }
}

static void MX_USART3_UART_Init(void)
{

    huart3.Instance          = USART3;
    huart3.Init.BaudRate     = 115200;
    huart3.Init.WordLength   = UART_WORDLENGTH_8B;
    huart3.Init.StopBits     = UART_STOPBITS_1;
    huart3.Init.Parity       = UART_PARITY_NONE;
    huart3.Init.Mode         = UART_MODE_TX_RX;
    huart3.Init.HwFlowCtl    = UART_HWCONTROL_NONE;
    huart3.Init.OverSampling = UART_OVERSAMPLING_16;
    if (HAL_UART_Init(&huart3) != HAL_OK)
    {
        Error_Handler();
    }
}

static void MX_USART6_UART_Init(void)
{

    huart6.Instance          = USART6;
    huart6.Init.BaudRate     = 115200;
    huart6.Init.WordLength   = UART_WORDLENGTH_8B;
    huart6.Init.StopBits     = UART_STOPBITS_1;
    huart6.Init.Parity       = UART_PARITY_NONE;
    huart6.Init.Mode         = UART_MODE_TX_RX;
    huart6.Init.HwFlowCtl    = UART_HWCONTROL_RTS_CTS;
    huart6.Init.OverSampling = UART_OVERSAMPLING_16;
    if (HAL_UART_Init(&huart6) != HAL_OK)
    {
        Error_Handler();
    }
}

static void MX_DMA_Init(void)
{

    /* DMA controller clock enable */
    __HAL_RCC_DMA1_CLK_ENABLE();
    __HAL_RCC_DMA2_CLK_ENABLE();

    /* DMA interrupt init */
    /* DMA1_Stream5_IRQn interrupt configuration */
    HAL_NVIC_SetPriority(DMA1_Stream5_IRQn, 0, 0);
    HAL_NVIC_EnableIRQ(DMA1_Stream5_IRQn);
    /* DMA1_Stream6_IRQn interrupt configuration */
    HAL_NVIC_SetPriority(DMA1_Stream6_IRQn, 0, 0);
    HAL_NVIC_EnableIRQ(DMA1_Stream6_IRQn);
    /* DMA2_Stream0_IRQn interrupt configuration */
    HAL_NVIC_SetPriority(DMA2_Stream0_IRQn, 0, 0);
    HAL_NVIC_EnableIRQ(DMA2_Stream0_IRQn);
    /* DMA2_Stream1_IRQn interrupt configuration */
    HAL_NVIC_SetPriority(DMA2_Stream1_IRQn, 0, 0);
    HAL_NVIC_EnableIRQ(DMA2_Stream1_IRQn);
    /* DMA2_Stream2_IRQn interrupt configuration */
    HAL_NVIC_SetPriority(DMA2_Stream2_IRQn, 0, 0);
    HAL_NVIC_EnableIRQ(DMA2_Stream2_IRQn);
}

static void MX_GPIO_Init(void)
{
    GPIO_InitTypeDef GPIO_InitStruct = {0};

    /* GPIO Ports Clock Enable */
    __HAL_RCC_GPIOE_CLK_ENABLE();
    __HAL_RCC_GPIOC_CLK_ENABLE();
    __HAL_RCC_GPIOF_CLK_ENABLE();
    __HAL_RCC_GPIOH_CLK_ENABLE();
    __HAL_RCC_GPIOA_CLK_ENABLE();
    __HAL_RCC_GPIOB_CLK_ENABLE();
    __HAL_RCC_GPIOG_CLK_ENABLE();
    __HAL_RCC_GPIOD_CLK_ENABLE();

    /*Configure GPIO pin Output Level */
    HAL_GPIO_WritePin(GPIOE, GPIO_PIN_2 | GPIO_PIN_3 | GPIO_PIN_4 | GPIO_PIN_5 | GPIO_PIN_6 | GPIO_PIN_0 | GPIO_PIN_1, GPIO_PIN_RESET);

    /*Configure GPIO pin Output Level */
    HAL_GPIO_WritePin(MPU_INT_GPIO_Port, MPU_INT_Pin, GPIO_PIN_RESET);

    /*Configure GPIO pin Output Level */
    HAL_GPIO_WritePin(GPIOF, mpu_int_Pin | mpu_fsync_Pin | lcd_command_Pin | lcd_cs_Pin | rfm_cs_Pin, GPIO_PIN_RESET);

    /*Configure GPIO pin Output Level */
    HAL_GPIO_WritePin(lcd_reset_GPIO_Port, lcd_reset_Pin, GPIO_PIN_RESET);

    /*Configure GPIO pins : PE2 PE3 PE4 PE5
                           PE6 PE0 PE1 */
    GPIO_InitStruct.Pin   = GPIO_PIN_2 | GPIO_PIN_3 | GPIO_PIN_4 | GPIO_PIN_5 | GPIO_PIN_6 | GPIO_PIN_0 | GPIO_PIN_1;
    GPIO_InitStruct.Mode  = GPIO_MODE_OUTPUT_PP;
    GPIO_InitStruct.Pull  = GPIO_NOPULL;
    GPIO_InitStruct.Speed = GPIO_SPEED_FREQ_LOW;
    HAL_GPIO_Init(GPIOE, &GPIO_InitStruct);

    /*Configure GPIO pin : MPU_Fsync_Pin */
    GPIO_InitStruct.Pin  = MPU_Fsync_Pin;
    GPIO_InitStruct.Mode = GPIO_MODE_INPUT;
    GPIO_InitStruct.Pull = GPIO_NOPULL;
    HAL_GPIO_Init(MPU_Fsync_GPIO_Port, &GPIO_InitStruct);

    /*Configure GPIO pin : MPU_INT_Pin */
    GPIO_InitStruct.Pin   = MPU_INT_Pin;
    GPIO_InitStruct.Mode  = GPIO_MODE_OUTPUT_PP;
    GPIO_InitStruct.Pull  = GPIO_NOPULL;
    GPIO_InitStruct.Speed = GPIO_SPEED_FREQ_LOW;
    HAL_GPIO_Init(MPU_INT_GPIO_Port, &GPIO_InitStruct);

    /*Configure GPIO pins : mpu_int_Pin mpu_fsync_Pin lcd_command_Pin lcd_cs_Pin
                           rfm_cs_Pin */
    GPIO_InitStruct.Pin   = mpu_int_Pin | mpu_fsync_Pin | lcd_command_Pin | lcd_cs_Pin | rfm_cs_Pin;
    GPIO_InitStruct.Mode  = GPIO_MODE_OUTPUT_PP;
    GPIO_InitStruct.Pull  = GPIO_NOPULL;
    GPIO_InitStruct.Speed = GPIO_SPEED_FREQ_LOW;
    HAL_GPIO_Init(GPIOF, &GPIO_InitStruct);

    /*Configure GPIO pin : rfm_irq_Pin */
    GPIO_InitStruct.Pin  = rfm_irq_Pin;
    GPIO_InitStruct.Mode = GPIO_MODE_INPUT;
    GPIO_InitStruct.Pull = GPIO_NOPULL;
    HAL_GPIO_Init(rfm_irq_GPIO_Port, &GPIO_InitStruct);

    /*Configure GPIO pin : lcd_reset_Pin */
    GPIO_InitStruct.Pin   = lcd_reset_Pin;
    GPIO_InitStruct.Mode  = GPIO_MODE_OUTPUT_PP;
    GPIO_InitStruct.Pull  = GPIO_NOPULL;
    GPIO_InitStruct.Speed = GPIO_SPEED_FREQ_LOW;
    HAL_GPIO_Init(lcd_reset_GPIO_Port, &GPIO_InitStruct);

    /*Configure GPIO pin : rs485_de_Pin */
    GPIO_InitStruct.Pin  = rs485_de_Pin;
    GPIO_InitStruct.Mode = GPIO_MODE_INPUT;
    GPIO_InitStruct.Pull = GPIO_NOPULL;
    HAL_GPIO_Init(rs485_de_GPIO_Port, &GPIO_InitStruct);
}

void HAL_TIM_PeriodElapsedCallback(TIM_HandleTypeDef* htim)
{
    if (htim->Instance == TIM14)
    {
        HAL_IncTick();
    }
}

void Error_Handler(void)
{
    __disable_irq();
    while (1)
    {
    }
}
